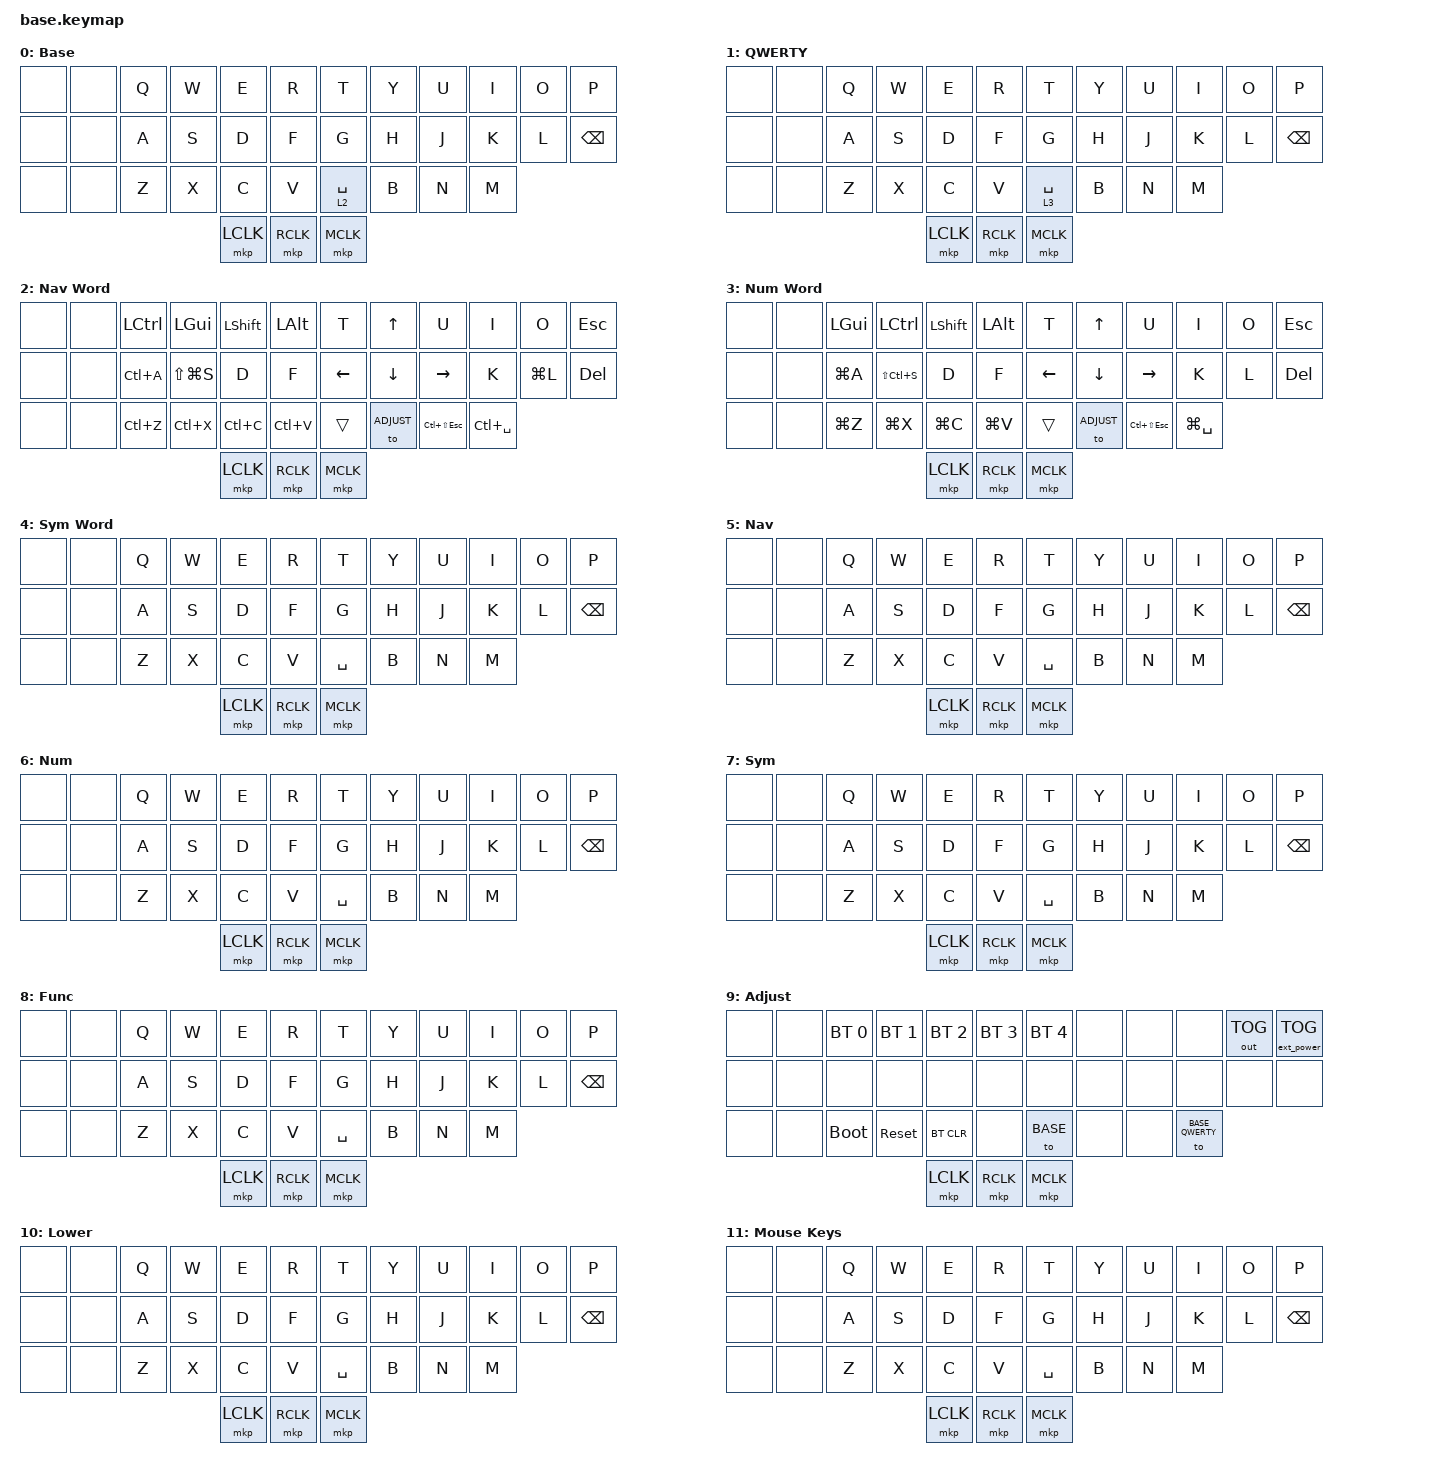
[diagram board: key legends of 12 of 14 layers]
/*
 * Copyright (c) 2020 The ZMK Contributors
 *
 * SPDX-License-Identifier: MIT
 */

// Define layer numbers
#define BASE 0
#define BASE_QWERTY 1
#define NAV_WORD 2
#define NUM_WORD 3
#define SYM_WORD 4
#define NAV 5
#define NUM 6
#define SYM 7
#define FUNC 8
#define ADJUST 9
#define LOWER 10
#define MOUSE_KEYS 11
#define MOUSE_TP 12
#define MOUSE_TP_SET 13

#ifdef HAS_UROB
  #define HAS_TRI_STATE
  #define HAS_NUM_WORD
#endif

// ZMK includes
#include <behaviors.dtsi>
#include <dt-bindings/zmk/keys.h>
#include <dt-bindings/zmk/bt.h>
#include <dt-bindings/zmk/rgb.h>
#include <dt-bindings/zmk/ext_power.h>
#include <dt-bindings/zmk/outputs.h>

// Personal includes
// #include "includes/custom_keycodes.dtsi"
// #include "includes/settings.dtsi"
//#include "includes/settings_pd.dtsi"
// #include "includes/conditional_layers.dtsi"
// #include "includes/macros.dtsi"
// #include "includes/combos.dtsi"
// #include "includes/behaviours_homerow_mods.dtsi"
// #include "includes/behaviours_mod_morph.dtsi"
// #include "includes/behaviours_other.dtsi"
#include "includes/mouse_keys.dtsi"
#include "includes/mouse_tp.dtsi"
// #include "includes/mouse_tp_badjeff_input_listener.dtsi"


#ifdef HAS_MOUSE_TP
  #define U_TOG_TP_SET &tog MOUSE_TP_SET
#else
  #define U_TOG_TP_SET &none
#endif  // HAS_MOUSE_TP


/ {

  keymap {
    compatible = "zmk,keymap";

    Base_layer {
      display-name = "Base";
      bindings = <
// ╭────────────────────────┬────────────────────────┬────────────────────────┬────────────────────────┬────────────────────────┬────────────────────────╮    ╭────────────────────────┬────────────────────────┬────────────────────────┬───────────────────────┬────────────────────────┬────────────────────────╮
     &none         &none      &kp Q                    &kp W                    &kp E                    &kp R                    &kp T                         &kp Y                    &kp U                    &kp I                    &kp O                    &kp P         
// ├────────────────────────┼────────────────────────┼────────────────────────┼────────────────────────┼────────────────────────┼────────────────────────┤    ├────────────────────────┼────────────────────────┼────────────────────────┼───────────────────────┼────────────────────────┼────────────────────────┤
     &none         &none      &kp A                    &kp S                    &kp D                    &kp F                    &kp G                         &kp H                    &kp J                    &kp K                    &kp L                    &kp BSPC            
// ├────────────────────────┼────────────────────────┼────────────────────────┼────────────────────────┼────────────────────────┼────────────────────────┤    ├────────────────────────┼────────────────────────┼────────────────────────┼───────────────────────┼────────────────────────┼────────────────────────┤
     &none         &none      &kp Z                    &kp X                    &kp C                    &kp V                    &lt 2 SPACE                   &kp B                    &kp N                    &kp M                                    
// ╰────────────────────────┴────────────────────────┴────────────────────────┴────────────────────────┼────────────────────────┼────────────────────────┤    ├────────────────────────┼────────────────────────┼────────────────────────┼───────────────────────┼────────────────────────┼────────────────────────╯
                                                                                &mkp LCLK                &mkp RCLK                &mkp MCLK      
//                                                                            ╰────────────────────────┴────────────────────────┴────────────────────────╯    ╰────────────────────────┴────────────────────────┴────────────────────────╯

      >;
       sensor-bindings = <&inc_dec_kp C_VOL_UP C_VOL_DN>;
    };

    Base_Qwerty_layer {
      display-name = "QWERTY";
      bindings = <
// ╭────────────────────────┬────────────────────────┬────────────────────────┬────────────────────────┬────────────────────────┬────────────────────────╮    ╭────────────────────────┬────────────────────────┬────────────────────────┬────────────────────────┬────────────────────────┬────────────────────────╮
     &none         &none      &kp Q                    &kp W                    &kp E                    &kp R                    &kp T                         &kp Y                    &kp U                    &kp I                    &kp O                    &kp P         
// ├────────────────────────┼────────────────────────┼────────────────────────┼────────────────────────┼────────────────────────┼────────────────────────┤    ├────────────────────────┼────────────────────────┼────────────────────────┼───────────────────────┼────────────────────────┼────────────────────────┤
     &none         &none      &kp A                    &kp S                    &kp D                    &kp F                    &kp G                         &kp H                    &kp J                    &kp K                    &kp L                    &kp BSPC            
// ├────────────────────────┼────────────────────────┼────────────────────────┼────────────────────────┼────────────────────────┼────────────────────────┤    ├────────────────────────┼────────────────────────┼────────────────────────┼───────────────────────┼────────────────────────┼────────────────────────┤
     &none         &none      &kp Z                    &kp X                    &kp C                    &kp V                    &lt 3 SPACE                   &kp B                    &kp N                    &kp M                                    
// ╰────────────────────────┴────────────────────────┴────────────────────────┴────────────────────────┼────────────────────────┼────────────────────────┤    ├────────────────────────┼────────────────────────┼────────────────────────┼───────────────────────┼────────────────────────┼────────────────────────╯
                                                                                &mkp LCLK                &mkp RCLK                &mkp MCLK 
//                                                                            ╰────────────────────────┴────────────────────────┴────────────────────────╯    ╰────────────────────────┴────────────────────────┴────────────────────────╯
      >;
    };

    Nav_Word_layer {
      display-name = "Nav Word";
      bindings = <
// ╭────────────────────────┬────────────────────────┬────────────────────────┬────────────────────────┬────────────────────────┬────────────────────────╮    ╭────────────────────────┬────────────────────────┬────────────────────────┬────────────────────────┬────────────────────────┬────────────────────────╮
     &none         &none      &kp LCTRL                &kp LGUI                 &kp LSHIFT               &kp LALT                 &kp T                         &kp UP                   &kp U                    &kp I                    &kp O                    &kp ESC         
// ├────────────────────────┼────────────────────────┼────────────────────────┼────────────────────────┼────────────────────────┼────────────────────────┤    ├────────────────────────┼────────────────────────┼────────────────────────┼───────────────────────┼────────────────────────┼────────────────────────┤
     &none         &none      &kp LC(A)                &kp LS(LG(S))            &kp D                    &kp F                    &kp LEFT                      &kp DOWN                 &kp RIGHT                &kp K                    &kp LG(L)                &kp DEL            
// ├────────────────────────┼────────────────────────┼────────────────────────┼────────────────────────┼────────────────────────┼────────────────────────┤    ├────────────────────────┼────────────────────────┼────────────────────────┼───────────────────────┼────────────────────────┼────────────────────────┤
     &none         &none      &kp LC(Z)                &kp LC(X)                &kp LC(C)                &kp LC(V)                &trans                        &to ADJUST               &kp LC(LS(ESC))          &kp LC(SPACE)                                   
// ╰────────────────────────┴────────────────────────┴────────────────────────┴────────────────────────┼────────────────────────┼────────────────────────┤    ├────────────────────────┼────────────────────────┼────────────────────────┼───────────────────────┼────────────────────────┼────────────────────────╯
                                                                                &mkp LCLK                &mkp RCLK                &mkp MCLK
//                                                                            ╰────────────────────────┴────────────────────────┴────────────────────────╯    ╰────────────────────────┴────────────────────────┴────────────────────────╯
      >;
     //  sensor-bindings = <&inc_dec_kp C_BRI_DN C_BRI_UP &inc_dec_kp LEFT RIGHT>;
    };

    Num_Word_layer {
      display-name = "Num Word";
      bindings = <
// ╭────────────────────────┬────────────────────────┬────────────────────────┬────────────────────────┬────────────────────────┬────────────────────────╮    ╭────────────────────────┬────────────────────────┬────────────────────────┬────────────────────────┬────────────────────────┬────────────────────────╮
     &none         &none      &kp LGUI                 &kp LCTRL                &kp LSHIFT               &kp LALT                 &kp T                         &kp UP                   &kp U                    &kp I                    &kp O                    &kp ESC        
// ├────────────────────────┼────────────────────────┼────────────────────────┼────────────────────────┼────────────────────────┼────────────────────────┤    ├────────────────────────┼────────────────────────┼────────────────────────┼───────────────────────┼────────────────────────┼────────────────────────┤
     &none         &none      &kp LG(A)                &kp LS(LC(S))            &kp D                    &kp F                    &kp LEFT                      &kp DOWN                 &kp RIGHT                &kp K                    &kp L                    &kp DEL            
// ├────────────────────────┼────────────────────────┼────────────────────────┼────────────────────────┼────────────────────────┼────────────────────────┤    ├────────────────────────┼────────────────────────┼────────────────────────┼───────────────────────┼────────────────────────┼────────────────────────┤
     &none         &none      &kp LG(Z)                &kp LG(X)                &kp LG(C)                &kp LG(V)                &trans                        &to ADJUST               &kp LC(LS(ESC))          &kp LG(SPACE)                                   
// ╰────────────────────────┴────────────────────────┴────────────────────────┴────────────────────────┼────────────────────────┼────────────────────────┤    ├────────────────────────┼────────────────────────┼────────────────────────┼───────────────────────┼────────────────────────┼────────────────────────╯
                                                                                &mkp LCLK                &mkp RCLK                &mkp MCLK 
//                                                                            ╰────────────────────────┴────────────────────────┴────────────────────────╯    ╰────────────────────────┴────────────────────────┴────────────────────────╯
      >;
     //  sensor-bindings = <&inc_dec_kp C_BRI_DN C_BRI_UP &inc_dec_kp LEFT RIGHT>;
    };

    Sym_Word_layer {
      display-name = "Sym Word";
      bindings = <
// ╭────────────────────────┬────────────────────────┬────────────────────────┬────────────────────────┬────────────────────────┬────────────────────────╮    ╭────────────────────────┬────────────────────────┬────────────────────────┬────────────────────────┬────────────────────────┬────────────────────────╮
     &none         &none      &kp Q                    &kp W                    &kp E                    &kp R                    &kp T                         &kp Y                    &kp U                    &kp I                    &kp O                    &kp P         
// ├────────────────────────┼────────────────────────┼────────────────────────┼────────────────────────┼────────────────────────┼────────────────────────┤    ├────────────────────────┼────────────────────────┼────────────────────────┼───────────────────────┼────────────────────────┼────────────────────────┤
     &none         &none      &kp A                    &kp S                    &kp D                    &kp F                    &kp G                         &kp H                    &kp J                    &kp K                    &kp L                    &kp BSPC            
// ├────────────────────────┼────────────────────────┼────────────────────────┼────────────────────────┼────────────────────────┼────────────────────────┤    ├────────────────────────┼────────────────────────┼────────────────────────┼───────────────────────┼────────────────────────┼────────────────────────┤
     &none         &none      &kp Z                    &kp X                    &kp C                    &kp V                    &kp SPACE                     &kp B                    &kp N                    &kp M                                    
// ╰────────────────────────┴────────────────────────┴────────────────────────┴────────────────────────┼────────────────────────┼────────────────────────┤    ├────────────────────────┼────────────────────────┼────────────────────────┼───────────────────────┼────────────────────────┼────────────────────────╯
                                                                                &mkp LCLK                &mkp RCLK                &mkp MCLK 
//                                                                            ╰────────────────────────┴────────────────────────┴────────────────────────╯    ╰────────────────────────┴────────────────────────┴────────────────────────╯
      >;
     //  sensor-bindings = <&inc_dec_kp C_BRI_DN C_BRI_UP &inc_dec_kp LEFT RIGHT>;
    };

    Nav_layer {
      display-name = "Nav";
      bindings = <
// ╭────────────────────────┬────────────────────────┬────────────────────────┬────────────────────────┬────────────────────────┬────────────────────────╮    ╭────────────────────────┬────────────────────────┬────────────────────────┬────────────────────────┬────────────────────────┬────────────────────────╮
     &none         &none      &kp Q                    &kp W                    &kp E                    &kp R                    &kp T                         &kp Y                    &kp U                    &kp I                    &kp O                    &kp P         
// ├────────────────────────┼────────────────────────┼────────────────────────┼────────────────────────┼────────────────────────┼────────────────────────┤    ├────────────────────────┼────────────────────────┼────────────────────────┼───────────────────────┼────────────────────────┼────────────────────────┤
     &none         &none      &kp A                    &kp S                    &kp D                    &kp F                    &kp G                         &kp H                    &kp J                    &kp K                    &kp L                    &kp BSPC            
// ├────────────────────────┼────────────────────────┼────────────────────────┼────────────────────────┼────────────────────────┼────────────────────────┤    ├────────────────────────┼────────────────────────┼────────────────────────┼───────────────────────┼────────────────────────┼────────────────────────┤
     &none         &none      &kp Z                    &kp X                    &kp C                    &kp V                    &kp SPACE                     &kp B                    &kp N                    &kp M                                    
// ╰────────────────────────┴────────────────────────┴────────────────────────┴────────────────────────┼────────────────────────┼────────────────────────┤    ├────────────────────────┼────────────────────────┼────────────────────────┼───────────────────────┼────────────────────────┼────────────────────────╯
                                                                                &mkp LCLK                &mkp RCLK                &mkp MCLK 
//                                                                            ╰────────────────────────┴────────────────────────┴────────────────────────╯    ╰────────────────────────┴────────────────────────┴────────────────────────╯
      >;
     //  sensor-bindings = <&inc_dec_kp C_BRI_DN C_BRI_UP &inc_dec_kp LEFT RIGHT>;
    };

    Num_layer {
      display-name = "Num";
      bindings = <
// ╭────────────────────────┬────────────────────────┬────────────────────────┬────────────────────────┬────────────────────────┬────────────────────────╮    ╭────────────────────────┬────────────────────────┬────────────────────────┬────────────────────────┬────────────────────────┬────────────────────────╮
     &none         &none      &kp Q                    &kp W                    &kp E                    &kp R                    &kp T                         &kp Y                    &kp U                    &kp I                    &kp O                    &kp P         
// ├────────────────────────┼────────────────────────┼────────────────────────┼────────────────────────┼────────────────────────┼────────────────────────┤    ├────────────────────────┼────────────────────────┼────────────────────────┼───────────────────────┼────────────────────────┼────────────────────────┤
     &none         &none      &kp A                    &kp S                    &kp D                    &kp F                    &kp G                         &kp H                    &kp J                    &kp K                    &kp L                    &kp BSPC            
// ├────────────────────────┼────────────────────────┼────────────────────────┼────────────────────────┼────────────────────────┼────────────────────────┤    ├────────────────────────┼────────────────────────┼────────────────────────┼───────────────────────┼────────────────────────┼────────────────────────┤
     &none         &none      &kp Z                    &kp X                    &kp C                    &kp V                    &kp SPACE                     &kp B                    &kp N                    &kp M                                    
// ╰────────────────────────┴────────────────────────┴────────────────────────┴────────────────────────┼────────────────────────┼────────────────────────┤    ├────────────────────────┼────────────────────────┼────────────────────────┼───────────────────────┼────────────────────────┼────────────────────────╯
                                                                                &mkp LCLK                &mkp RCLK                &mkp MCLK 
//                                                                            ╰────────────────────────┴────────────────────────┴────────────────────────╯    ╰────────────────────────┴────────────────────────┴────────────────────────╯
      >;
     //  sensor-bindings = <&inc_dec_kp C_BRI_DN C_BRI_UP &inc_dec_kp LEFT RIGHT>;
    };

    Sym_layer {
      display-name = "Sym";
      bindings = <
// ╭────────────────────────┬────────────────────────┬────────────────────────┬────────────────────────┬────────────────────────┬────────────────────────╮    ╭────────────────────────┬────────────────────────┬────────────────────────┬────────────────────────┬────────────────────────┬────────────────────────╮
     &none         &none      &kp Q                    &kp W                    &kp E                    &kp R                    &kp T                         &kp Y                    &kp U                    &kp I                    &kp O                    &kp P         
// ├────────────────────────┼────────────────────────┼────────────────────────┼────────────────────────┼────────────────────────┼────────────────────────┤    ├────────────────────────┼────────────────────────┼────────────────────────┼───────────────────────┼────────────────────────┼────────────────────────┤
     &none         &none      &kp A                    &kp S                    &kp D                    &kp F                    &kp G                         &kp H                    &kp J                    &kp K                    &kp L                    &kp BSPC            
// ├────────────────────────┼────────────────────────┼────────────────────────┼────────────────────────┼────────────────────────┼────────────────────────┤    ├────────────────────────┼────────────────────────┼────────────────────────┼───────────────────────┼────────────────────────┼────────────────────────┤
     &none         &none      &kp Z                    &kp X                    &kp C                    &kp V                    &kp SPACE                     &kp B                    &kp N                    &kp M                                    
// ╰────────────────────────┴────────────────────────┴────────────────────────┴────────────────────────┼────────────────────────┼────────────────────────┤    ├────────────────────────┼────────────────────────┼────────────────────────┼───────────────────────┼────────────────────────┼────────────────────────╯
                                                                                &mkp LCLK                &mkp RCLK                &mkp MCLK 
//                                                                            ╰────────────────────────┴────────────────────────┴────────────────────────╯    ╰────────────────────────┴────────────────────────┴────────────────────────╯
      >;
     //  sensor-bindings = <&inc_dec_kp C_BRI_DN C_BRI_UP &inc_dec_kp LEFT RIGHT>;
    };

    Func_layer {
      display-name = "Func";
      bindings = <
// ╭────────────────────────┬────────────────────────┬────────────────────────┬────────────────────────┬────────────────────────┬────────────────────────╮    ╭────────────────────────┬────────────────────────┬────────────────────────┬────────────────────────┬────────────────────────┬────────────────────────╮
     &none         &none      &kp Q                    &kp W                    &kp E                    &kp R                    &kp T                         &kp Y                    &kp U                    &kp I                    &kp O                    &kp P         
// ├────────────────────────┼────────────────────────┼────────────────────────┼────────────────────────┼────────────────────────┼────────────────────────┤    ├────────────────────────┼────────────────────────┼────────────────────────┼───────────────────────┼────────────────────────┼────────────────────────┤
     &none         &none      &kp A                    &kp S                    &kp D                    &kp F                    &kp G                         &kp H                    &kp J                    &kp K                    &kp L                    &kp BSPC            
// ├────────────────────────┼────────────────────────┼────────────────────────┼────────────────────────┼────────────────────────┼────────────────────────┤    ├────────────────────────┼────────────────────────┼────────────────────────┼───────────────────────┼────────────────────────┼────────────────────────┤
     &none         &none      &kp Z                    &kp X                    &kp C                    &kp V                    &kp SPACE                     &kp B                    &kp N                    &kp M                                    
// ╰────────────────────────┴────────────────────────┴────────────────────────┴────────────────────────┼────────────────────────┼────────────────────────┤    ├────────────────────────┼────────────────────────┼────────────────────────┼───────────────────────┼────────────────────────┼────────────────────────╯
                                                                                &mkp LCLK                &mkp RCLK                &mkp MCLK 
//                                                                            ╰────────────────────────┴────────────────────────┴────────────────────────╯    ╰────────────────────────┴────────────────────────┴────────────────────────╯
      >;
     //  sensor-bindings = <&inc_dec_kp C_BRI_DN C_BRI_UP &inc_dec_kp LEFT RIGHT>;
    };

    Adjust_layer {
      display-name = "Adjust";
      bindings = <
// ╭────────────────────────┬────────────────────────┬────────────────────────┬────────────────────────┬────────────────────────┬────────────────────────╮    ╭────────────────────────┬────────────────────────┬────────────────────────┬────────────────────────┬────────────────────────┬────────────────────────╮
     &none         &none      &bt  BT_SEL 0            &bt  BT_SEL 1            &bt  BT_SEL 2            &bt  BT_SEL 3            &bt  BT_SEL 4                 &none                    &none                    &none                    &out OUT_TOG             &ext_power EP_TOG        
// ├────────────────────────┼────────────────────────┼────────────────────────┼────────────────────────┼────────────────────────┼────────────────────────┤    ├────────────────────────┼────────────────────────┼────────────────────────┼───────────────────────┼────────────────────────┼────────────────────────┤
     &none         &none      &none                    &none                    &none                    &none                    &none                         &none                    &none                    &none                    &none                    &none        
// ├────────────────────────┼────────────────────────┼────────────────────────┼────────────────────────┼────────────────────────┼────────────────────────┤    ├────────────────────────┼────────────────────────┼────────────────────────┼───────────────────────┼────────────────────────┼────────────────────────┤
     &none         &none      &bootloader              &sys_reset               &bt BT_CLR               &none                    &to BASE                      &none                    &none                    &to BASE_QWERTY                                
// ╰────────────────────────┴────────────────────────┴────────────────────────┴────────────────────────┼────────────────────────┼────────────────────────┤    ├────────────────────────┼────────────────────────┼────────────────────────┼───────────────────────┼────────────────────────┼────────────────────────╯
                                                                                &mkp LCLK                &mkp RCLK                &mkp MCLK  
//                                                                            ╰────────────────────────┴────────────────────────┴────────────────────────╯    ╰────────────────────────┴────────────────────────┴────────────────────────╯
      >;
     //  sensor-bindings = <&inc_dec_kp C_BRI_DN C_BRI_UP &inc_dec_kp LEFT RIGHT>;
    };

    Lower_layer {
      display-name = "Lower";
      bindings = <
// ╭────────────────────────┬────────────────────────┬────────────────────────┬────────────────────────┬────────────────────────┬────────────────────────╮    ╭────────────────────────┬────────────────────────┬────────────────────────┬────────────────────────┬────────────────────────┬────────────────────────╮
     &none         &none      &kp Q                    &kp W                    &kp E                    &kp R                    &kp T                         &kp Y                    &kp U                    &kp I                    &kp O                    &kp P         
// ├────────────────────────┼────────────────────────┼────────────────────────┼────────────────────────┼────────────────────────┼────────────────────────┤    ├────────────────────────┼────────────────────────┼────────────────────────┼───────────────────────┼────────────────────────┼────────────────────────┤
     &none         &none      &kp A                    &kp S                    &kp D                    &kp F                    &kp G                         &kp H                    &kp J                    &kp K                    &kp L                    &kp BSPC            
// ├────────────────────────┼────────────────────────┼────────────────────────┼────────────────────────┼────────────────────────┼────────────────────────┤    ├────────────────────────┼────────────────────────┼────────────────────────┼───────────────────────┼────────────────────────┼────────────────────────┤
     &none         &none      &kp Z                    &kp X                    &kp C                    &kp V                    &kp SPACE                     &kp B                    &kp N                    &kp M                                    
// ╰────────────────────────┴────────────────────────┴────────────────────────┴────────────────────────┼────────────────────────┼────────────────────────┤    ├────────────────────────┼────────────────────────┼────────────────────────┼───────────────────────┼────────────────────────┼────────────────────────╯
                                                                                &mkp LCLK                &mkp RCLK                &mkp MCLK 
//                                                                            ╰────────────────────────┴────────────────────────┴────────────────────────╯    ╰────────────────────────┴────────────────────────┴────────────────────────╯
      >;
     //  sensor-bindings = <&inc_dec_kp C_BRI_DN C_BRI_UP &inc_dec_kp LEFT RIGHT>;
    };

// #ifdef HAS_MOUSE_KEYS
    MouseKeys_layer {
      display-name = "Mouse Keys";
      bindings = <
// ╭────────────────────────┬────────────────────────┬────────────────────────┬────────────────────────┬────────────────────────┬────────────────────────╮    ╭────────────────────────┬────────────────────────┬────────────────────────┬────────────────────────┬────────────────────────┬────────────────────────╮
     &none         &none      &kp Q                    &kp W                    &kp E                    &kp R                    &kp T                         &kp Y                    &kp U                    &kp I                    &kp O                    &kp P         
// ├────────────────────────┼────────────────────────┼────────────────────────┼────────────────────────┼────────────────────────┼────────────────────────┤    ├────────────────────────┼────────────────────────┼────────────────────────┼───────────────────────┼────────────────────────┼────────────────────────┤
     &none         &none      &kp A                    &kp S                    &kp D                    &kp F                    &kp G                         &kp H                    &kp J                    &kp K                    &kp L                    &kp BSPC            
// ├────────────────────────┼────────────────────────┼────────────────────────┼────────────────────────┼────────────────────────┼────────────────────────┤    ├────────────────────────┼────────────────────────┼────────────────────────┼───────────────────────┼────────────────────────┼────────────────────────┤
     &none         &none      &kp Z                    &kp X                    &kp C                    &kp V                    &kp SPACE                     &kp B                    &kp N                    &kp M                                    
// ╰────────────────────────┴────────────────────────┴────────────────────────┴────────────────────────┼────────────────────────┼────────────────────────┤    ├────────────────────────┼────────────────────────┼────────────────────────┼───────────────────────┼────────────────────────┼────────────────────────╯
                                                                                &mkp LCLK                &mkp RCLK                &mkp MCLK 
//                                                                            ╰────────────────────────┴────────────────────────┴────────────────────────╯    ╰────────────────────────┴────────────────────────┴────────────────────────╯
      >;
     //  sensor-bindings = <&inc_dec_kp C_BRI_DN C_BRI_UP &inc_dec_kp LEFT RIGHT>;
    };
// #endif

// #ifdef HAS_MOUSE_TP
    MouseTP_layer {
      display-name = "TP";
      bindings = <
// ╭────────────────────────┬────────────────────────┬────────────────────────┬────────────────────────┬────────────────────────┬────────────────────────╮    ╭────────────────────────┬────────────────────────┬────────────────────────┬────────────────────────┬────────────────────────┬────────────────────────╮
     &none         &none      &kp Q                    &kp W                    &kp E                    &kp R                    &kp T                         &kp Y                    &kp U                    &kp I                    &kp O                    &kp P         
// ├────────────────────────┼────────────────────────┼────────────────────────┼────────────────────────┼────────────────────────┼────────────────────────┤    ├────────────────────────┼────────────────────────┼────────────────────────┼───────────────────────┼────────────────────────┼────────────────────────┤
     &none         &none      &kp A                    &kp S                    &kp D                    &kp F                    &kp G                         &kp H                    &kp J                    &kp K                    &kp L                    &kp BSPC            
// ├────────────────────────┼────────────────────────┼────────────────────────┼────────────────────────┼────────────────────────┼────────────────────────┤    ├────────────────────────┼────────────────────────┼────────────────────────┼───────────────────────┼────────────────────────┼────────────────────────┤
     &none         &none      &kp Z                    &kp X                    &kp C                    &kp V                    &kp SPACE                     &kp B                    &kp N                    &kp M                                    
// ╰────────────────────────┴────────────────────────┴────────────────────────┴────────────────────────┼────────────────────────┼────────────────────────┤    ├────────────────────────┼────────────────────────┼────────────────────────┼───────────────────────┼────────────────────────┼────────────────────────╯
                                                                                &mkp LCLK                &mkp RCLK                &mkp MCLK 
//                                                                            ╰────────────────────────┴────────────────────────┴────────────────────────╯    ╰────────────────────────┴────────────────────────┴────────────────────────╯
      >;
     //  sensor-bindings = <&inc_dec_kp C_BRI_DN C_BRI_UP &inc_dec_kp LEFT RIGHT>;
    };

    MouseSettings_layer {
      display-name = "MouseSettings";
      bindings = <
// ╭────────────────────────┬────────────────────────┬────────────────────────┬────────────────────────┬────────────────────────┬────────────────────────╮    ╭────────────────────────┬────────────────────────┬────────────────────────┬────────────────────────┬────────────────────────┬────────────────────────╮
     &none         &none      &kp Q                    &kp W                    &kp E                    &kp R                    &kp T                         &kp Y                    &kp U                    &kp I                    &kp O                    &kp P         
// ├────────────────────────┼────────────────────────┼────────────────────────┼────────────────────────┼────────────────────────┼────────────────────────┤    ├────────────────────────┼────────────────────────┼────────────────────────┼───────────────────────┼────────────────────────┼────────────────────────┤
     &none         &none      &kp A                    &kp S                    &kp D                    &kp F                    &kp G                         &kp H                    &kp J                    &kp K                    &kp L                    &kp BSPC            
// ├────────────────────────┼────────────────────────┼────────────────────────┼────────────────────────┼────────────────────────┼────────────────────────┤    ├────────────────────────┼────────────────────────┼────────────────────────┼───────────────────────┼────────────────────────┼────────────────────────┤
     &none         &none      &kp Z                    &kp X                    &kp C                    &kp V                    &kp SPACE                     &kp B                    &kp N                    &kp M                                    
// ╰────────────────────────┴────────────────────────┴────────────────────────┴────────────────────────┼────────────────────────┼────────────────────────┤    ├────────────────────────┼────────────────────────┼────────────────────────┼───────────────────────┼────────────────────────┼────────────────────────╯
                                                                                &mkp LCLK                &mkp RCLK                &mkp MCLK 
//                                                                            ╰────────────────────────┴────────────────────────┴────────────────────────╯    ╰────────────────────────┴────────────────────────┴────────────────────────╯
      >;
     //  sensor-bindings = <&inc_dec_kp C_BRI_DN C_BRI_UP &inc_dec_kp LEFT RIGHT>;
    };
// #endif
  };

behaviors {
        scrl_encoder: scrl_encoder {
            compatible = "zmk,behavior-sensor-rotate";
            #sensor-binding-cells = <0>;
            bindings = <&msc SCRL_UP>, <&msc SCRL_DOWN>;
        };
    };

combos {
        compatible = "zmk,combos";

combo_tab {
            timeout-ms = <50>;
            key-positions = <2 3>;
            bindings = <&kp TAB>;
        };

combo_caps {
            timeout-ms = <50>;
            key-positions = <14 15>;
            bindings = <&kp CAPS>;
        };

combo_1 {
            timeout-ms = <50>;
            key-positions = <2 14>;
            bindings = <&kp N1>;
        };

combo_2 {
            timeout-ms = <50>;
            key-positions = <3 15>;
            bindings = <&kp N2>;
        };

combo_3 {
            timeout-ms = <50>;
            key-positions = <4 16>;
            bindings = <&kp N3>;
        };

combo_4 {
            timeout-ms = <50>;
            key-positions = <5 17>;
            bindings = <&kp N4>;
        };

combo_5 {
            timeout-ms = <50>;
            key-positions = <6 18>;
            bindings = <&kp N5>;
        };

combo_6 {
            timeout-ms = <50>;
            key-positions = <7 19>;
            bindings = <&kp N6>;
        };

combo_7 {
            timeout-ms = <50>;
            key-positions = <8 20>;
            bindings = <&kp N7>;
        };

combo_8 {
            timeout-ms = <50>;
            key-positions = <9 21>;
            bindings = <&kp N8>;
        };

combo_9 {
            timeout-ms = <50>;
            key-positions = <10 22>;
            bindings = <&kp N9>;
        };

combo_0 {
            timeout-ms = <50>;
            key-positions = <11 23>;
            bindings = <&kp N0>;
        };

combo_minus {
            timeout-ms = <50>;
            key-positions = <8 9>;
            bindings = <&kp MINUS>;
        };

combo_equal {
            timeout-ms = <50>;
            key-positions = <9 10>;
            bindings = <&kp EQUAL>;
        };

combo_comma {
            timeout-ms = <50>;
            key-positions = <26 27>;
            bindings = <&kp COMMA>;
        };

combo_dot {
            timeout-ms = <50>;
            key-positions = <28 29>;
            bindings = <&kp DOT>;
        };

combo_questionmark {
            timeout-ms = <50>;
            key-positions = <32 33>;
            bindings = <&kp RS(SLASH)>;
        };

combo_colon {
            timeout-ms = <50>;
            key-positions = <15 16>;
            bindings = <&kp RS(SEMI)>;
        };

combo_semi {
            timeout-ms = <50>;
            key-positions = <15 16 17>;
            bindings = <&kp SEMI>;
        };

combo_quote {
            timeout-ms = <50>;
            key-positions = <21 22>;
            bindings = <&kp RS(SQT)>;
        };

combo_sqt {
            timeout-ms = <50>;
            key-positions = <20 21 22>;
            bindings = <&kp SQT>;
        };

combo_lsbkt {
            timeout-ms = <50>;
            key-positions = <17 18>;
            bindings = <&kp RS(N9)>;
        };

combo_rsbkt {
            timeout-ms = <50>;
            key-positions = <19 20>;
            bindings = <&kp RS(N0)>;
        };

combo_lbkt {
            timeout-ms = <50>;
            key-positions = <16 17 18>;
            bindings = <&kp LBKT>;
        };

combo_rbkt {
            timeout-ms = <50>;
            key-positions = <19 20 21>;
            bindings = <&kp RBKT>;
        };

combo_lbbkt {
            timeout-ms = <50>;
            key-positions = <15 16 17 18>;
            bindings = <&kp RS(LBKT)>;
        };

combo_rbbkt {
            timeout-ms = <50>;
            key-positions = <19 20 21 22>;
            bindings = <&kp RS(RBKT)>;
        };

combo_bslh {
            timeout-ms = <50>;
            key-positions = <26 27 28 29>;
            bindings = <&kp BSLH>;
        };

combo_exclamation {
            timeout-ms = <50>;
            key-positions = <31 32 33>;
            bindings = <&kp RS(N1)>;
        };

combo_langlebk {
            timeout-ms = <50>;
            key-positions = <26 27 28>;
            bindings = <&kp RS(COMMA)>;
        };

combo_ranglebk {
            timeout-ms = <50>;
            key-positions = <27 28 29>;
            bindings = <&kp RS(DOT)>;
        };

combo_enter {
            timeout-ms = <50>;
            key-positions = <22 23>;
            bindings = <&kp ENTER>;
        };

combo_at {
            timeout-ms = <50>;
            key-positions = <6 14>;
            bindings = <&kp RS(N2)>;
        };
   
   combo_and {
            timeout-ms = <50>;
            key-positions = <14 16>;
            bindings = <&kp RS(N7)>;
        };

combo_percent {
            timeout-ms = <50>;
            key-positions = <11 28>;
            bindings = <&kp RS(N5)>;
        };

combo_dollar {
            timeout-ms = <50>;
            key-positions = <16 22>;
            bindings = <&kp RS(N4)>;
        };

combo_poundsign {
            timeout-ms = <50>;
            key-positions = <11 15>;
            bindings = <&kp RS(N3)>;
        };


combo_plus {
            timeout-ms = <50>;
            key-positions = <11 22>;
            bindings = <&kp RS(EQUAL)>;
        };

combo_underline {
            timeout-ms = <50>;
            key-positions = <8 22>;
            bindings = <&kp RS(MINUS)>;
        };

combo_multiply {
            timeout-ms = <50>;
            key-positions = <11 33>;
            bindings = <&kp RS(N8)>;
        };

combo_divide {
            timeout-ms = <50>;
            key-positions = <16 29>;
            bindings = <&kp SLASH>;
        };

combo_power {
            timeout-ms = <50>;
            key-positions = <3 11>;
            bindings = <&kp RS(N6)>;
        };

combo_wave {
            timeout-ms = <50>;
            key-positions = <3 4>;
            bindings = <&kp RS(GRAVE)>;
        };

combo_grave {
            timeout-ms = <50>;
            key-positions = <3 4 5>;
            bindings = <&kp GRAVE>;
        };

      };
};
